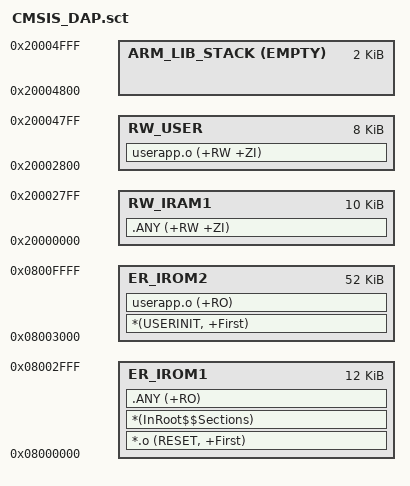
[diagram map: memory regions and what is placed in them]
; *************************************************************
; *** Scatter-Loading Description File generated by uVision ***
; *************************************************************

LR_IROM1 0x08000000 0x00010000
{	; load region size_region
	ER_IROM1 0x08000000 0x0003000
	{	; load address = execution address
		*.o (RESET, +First)
		*(InRoot$$Sections)
		.ANY (+RO)
	}

	ARM_LIB_STACK 0x20005000 EMPTY -0x800
	{ }
	RW_IRAM1 0x20000000 0x00002800	; 2200
	{	; RW data
		.ANY (+RW +ZI)
	}
	RW_USER 0x20002800 0x00002000	; 2200
	{
		userapp.o (+RW +ZI)
	}
}

LR_IROM2 0x08003000 0x0000D000  {
	ER_IROM2 0x08003000 0x0000D000  {  ; load address = execution address
		*(USERINIT, +First)
		userapp.o (+RO)
	}
}
